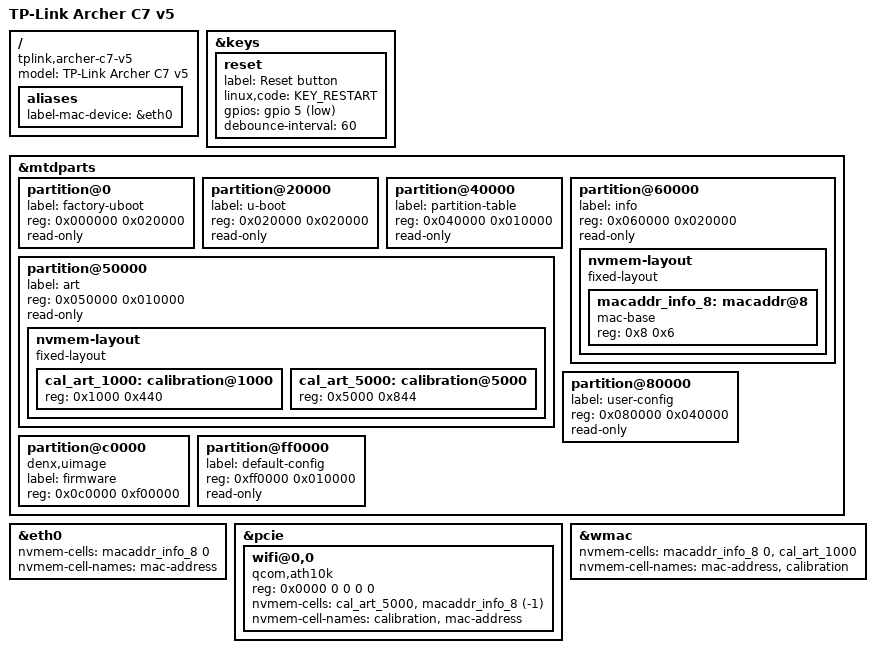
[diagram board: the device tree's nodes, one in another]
// SPDX-License-Identifier: GPL-2.0-or-later OR MIT

#include "qca9563_tplink_archer-x7-v5.dtsi"

/ {
	compatible = "tplink,archer-c7-v5", "qca,qca9563";
	model = "TP-Link Archer C7 v5";

	aliases {
		label-mac-device = &eth0;
	};
};

&keys {
	reset {
		label = "Reset button";
		linux,code = <KEY_RESTART>;
		gpios = <&gpio 5 GPIO_ACTIVE_LOW>;
		debounce-interval = <60>;
	};
};

&mtdparts {
	partition@0 {
		label = "factory-uboot";
		reg = <0x000000 0x020000>;
		read-only;
	};

	partition@20000 {
		label = "u-boot";
		reg = <0x020000 0x020000>;
		read-only;
	};

	partition@40000 {
		label = "partition-table";
		reg = <0x040000 0x010000>;
		read-only;
	};

	partition@50000 {
		label = "art";
		reg = <0x050000 0x010000>;
		read-only;

		nvmem-layout {
			compatible = "fixed-layout";
			#address-cells = <1>;
			#size-cells = <1>;

			cal_art_1000: calibration@1000 {
				reg = <0x1000 0x440>;
			};

			cal_art_5000: calibration@5000 {
				reg = <0x5000 0x844>;
			};
		};
	};

	partition@60000 {
		label = "info";
		reg = <0x060000 0x020000>;
		read-only;

		nvmem-layout {
			compatible = "fixed-layout";
			#address-cells = <1>;
			#size-cells = <1>;

			macaddr_info_8: macaddr@8 {
				compatible = "mac-base";
				reg = <0x8 0x6>;
				#nvmem-cell-cells = <1>;
			};
		};
	};

	partition@80000 {
		label = "user-config";
		reg = <0x080000 0x040000>;
		read-only;
	};

	partition@c0000 {
		label = "firmware";
		reg = <0x0c0000 0xf00000>;
		compatible = "denx,uimage";
	};

	partition@ff0000 {
		label = "default-config";
		reg = <0xff0000 0x010000>;
		read-only;
	};
};

&eth0 {
	nvmem-cells = <&macaddr_info_8 0>;
	nvmem-cell-names = "mac-address";
};

&pcie {
	status = "okay";

	wifi@0,0 {
		compatible = "qcom,ath10k";
		reg = <0x0000 0 0 0 0>;
		nvmem-cells = <&cal_art_5000>, <&macaddr_info_8 (-1)>;
		nvmem-cell-names = "calibration", "mac-address";
	};
};

&wmac {
	nvmem-cells = <&macaddr_info_8 0>, <&cal_art_1000>;
	nvmem-cell-names = "mac-address", "calibration";
};
